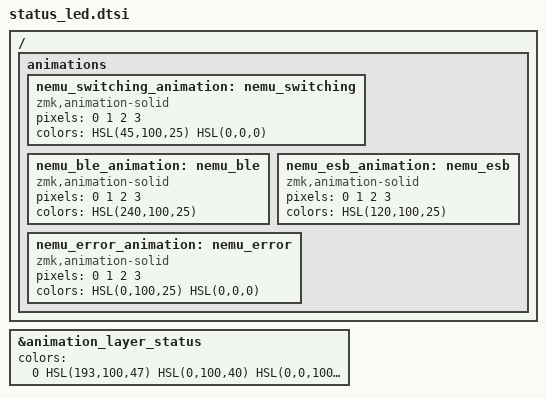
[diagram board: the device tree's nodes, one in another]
/* Restore the original strip, power gate, animation controller and XIAO LEDs. */
#include "../GeaconEquinox/GeaconEquinox_led.dtsi"
/ {
    animations {
        nemu_switching_animation: nemu_switching {
            compatible = "zmk,animation-solid";
            pixels = <0 1 2 3>;
            colors = <HSL(45,100,25) HSL(0,0,0)>;
        };
        nemu_ble_animation: nemu_ble {
            compatible = "zmk,animation-solid";
            pixels = <0 1 2 3>;
            colors = <HSL(240,100,25)>;
        };
        nemu_esb_animation: nemu_esb {
            compatible = "zmk,animation-solid";
            pixels = <0 1 2 3>;
            colors = <HSL(120,100,25)>;
        };
        nemu_error_animation: nemu_error {
            compatible = "zmk,animation-solid";
            pixels = <0 1 2 3>;
            colors = <HSL(0,100,25) HSL(0,0,0)>;
        };
    };
};

/* Def, Fnc, Mouse, Scr, BT, Dial, Mac, MacDial. */
&animation_layer_status {
    colors = <0 HSL(193,100,47) HSL(0,100,40) HSL(0,0,100)
              HSL(29,88,51) HSL(270,100,45) HSL(120,100,40) HSL(320,100,45)>;
};
